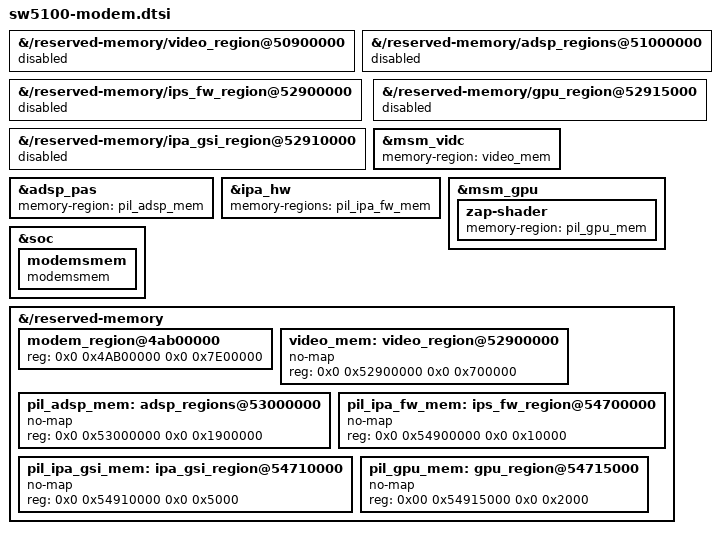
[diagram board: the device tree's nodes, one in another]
// SPDX-License-Identifier: GPL-2.0

// All these memory regions are allocated out of PIL Reserved
// boot_images/QcomPkg/SocPkg/AthertonPkg/LA./uefiplat.cfg
// and OEM_pil_subsys_load_region_size
// trustzone_images/ssg/securemsm/trustzone/qsee/mink/oem/config/atherton/oem_config.xml
&{/reserved-memory/video_region@50900000} {
	status = "disabled";
};

&{/reserved-memory/adsp_regions@51000000} {
	status = "disabled";
};

&{/reserved-memory/ips_fw_region@52900000} {
	status = "disabled";
};

&{/reserved-memory/ipa_gsi_region@52910000} {
	status = "disabled";
};

&{/reserved-memory/gpu_region@52915000} {
	status = "disabled";
};

/ {
	fragment@reserved-memory {
		target-path = "/reserved-memory";
		__overlay__ {
			#address-cells = <2>;
			#size-cells = <2>;
			modem_region@4ab00000 {
				// increase size by 32MB (0x05E00000 -> 0x07E00000)
				reg = <0x0 0x4AB00000 0x0 0x7E00000>;
			};

			video_mem: video_region@52900000 {
				no-map;
				reg = <0x0 0x52900000 0x0 0x700000>;
			};

			pil_adsp_mem: adsp_regions@53000000 {
				no-map;
				reg = <0x0 0x53000000 0x0 0x1900000>;
			};

			pil_ipa_fw_mem: ips_fw_region@54700000 {
				no-map;
				reg = <0x0 0x54900000 0x0 0x10000>;
			};

			pil_ipa_gsi_mem: ipa_gsi_region@54710000 {
				no-map;
				reg = <0x0 0x54910000 0x0 0x5000>;
			};

			pil_gpu_mem: gpu_region@54715000 {
				no-map;
				reg = <0x00 0x54915000 0x0 0x2000>;
			};
		};
	};
};

&msm_vidc {
	memory-region = <&video_mem>;
};

&adsp_pas {
	memory-region = <&pil_adsp_mem>;
};

&ipa_hw {
	memory-regions = <&pil_ipa_fw_mem>;
};

&msm_gpu {
	zap-shader {
		memory-region = <&pil_gpu_mem>;
	};
};

&soc {
	modemsmem {
		compatible = "modemsmem";
	};
};
